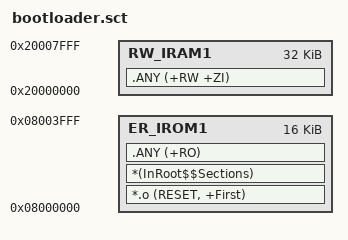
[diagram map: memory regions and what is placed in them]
; STM32F303CBT6 - 128 KiB Flash
; 16 KiB bootloader + 54 KiB MAIN + 54 KiB BACKUP + 2 x 2 KiB settings

LR_IROM1 0x08000000 0x00004000
{
    ER_IROM1 0x08000000 0x00004000
    {
        *.o (RESET, +First)
        *(InRoot$$Sections)
        .ANY (+RO)
    }

    RW_IRAM1 0x20000000 0x00008000
    {
        .ANY (+RW +ZI)
    }
}
